# A31G12x_series register map
Vendor: ABOV Semiconductor Co., Ltd.; Series: A31G12x_series; File version: 1.0
CPU: CM0PLUS r0p1, little endian, no MPU, no FPU, VTOR, 2 interrupt priority bits
Registers are 32-bit, read-write, reset 0x0 unless marked. A register's access mark holds for its fields unless they carry their own. Offsets are from the block's base; [hi:lo] are bit positions; {n}, {i} and the like mark numbered series.

## xNVIC — NESTED VECTORED INTERRUPT CONTROLLER
Base 0xE000E100
0x00 ISER — Interrupt Set-enable Register
0x80 ICER — Interrupt Clear-enable Register
0x100 ISPR — Interrupt Set-pending Register
0x180 ICPR — Interrupt Clear-pending Register
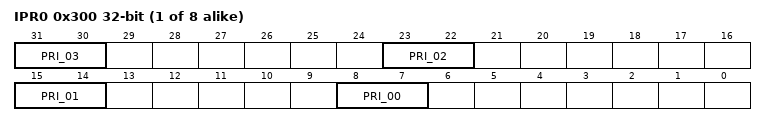
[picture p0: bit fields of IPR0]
{0x300+4i} IPR{i} (reset mask 0xC0C0C0C0) (i=0..7) — Interrupt Priority Register {i}
  [31:30] PRI_{4i+3:02} — IRQ {4i+3:02} Priority. The lower the value, the greater the priority of the corresponding interrupt.
  [23:22] PRI_{4i+2:02} — IRQ {4i+2:02} Priority. The lower the value, the greater the priority of the corresponding interrupt.
  [15:14] PRI_{4i+1:02} — IRQ {4i+1:02} Priority. The lower the value, the greater the priority of the corresponding interrupt.
  [8:7] PRI_{4i:02} — IRQ {4i:02} Priority. The lower the value, the greater the priority of the corresponding interrupt.

## xSCB — SYSTEM CONTROL BLOCK
Base 0xE000ED00
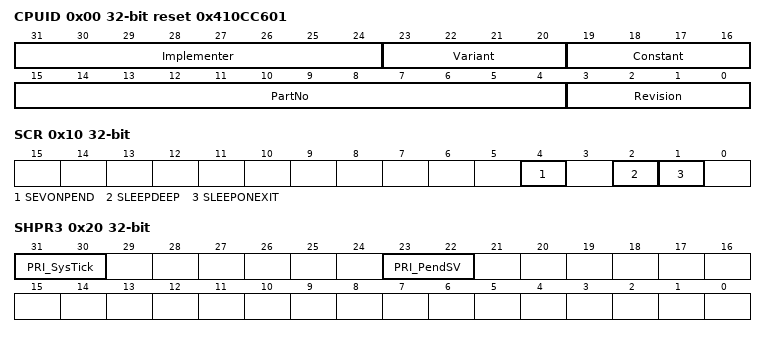
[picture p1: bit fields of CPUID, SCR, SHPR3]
0x00 CPUID ro reset 0x410CC601
  [31:24] Implementer — Implementer Code (0x41 corresponds to ARM)
  [23:20] Variant — Major revision number n in the rnpm revision status
  [19:16] Constant — Constant that defines the architecture of the processor (0xC corresponds to ARMv6-M architecture)
  [15:4] PartNo — Part number of the processor (0xC60 corresponds to Cortex-M0)
  [3:0] Revision — Minor revision number m in the rnpm revision status (0x1 corresponds to patch 1)
0x04 ICSR (reset mask 0x9E03F000) — Interrupt Control and State Register
0x08 VTOR (reset mask 0xFFFFFF80) — Vector Table Offset Register
0x0C AIRCR (reset mask 0xFFFF8006) — Application Interrupt and Reset Control Register
0x10 SCR — System Control Register
  [4] SEVONPEND — Send Event on Pending bit
  [2] SLEEPDEEP — Controls whether the processor uses sleep or deep sleep as its low power mode
  [1] SLEEPONEXIT — Indicates sleep-on-exit when returning from Handler mode to Thread mode
0x14 CCR ro (reset mask 0x208) — Configuration and Control Register
0x1C SHPR2 — System Handler Priority Register 2
  [31:30] PRI_SVCall — Priority of System Handler 11, SVCall. The lower the value, the greater the priority of the corresponding interrupt.
0x20 SHPR3 — System Handler Priority Register 3
  [31:30] PRI_SysTick — Priority of System Handler 15, SysTick. The lower the value, the greater the priority of the corresponding interrupt.
  [23:22] PRI_PendSV — Priority of System Handler 14, PendSV. The lower the value, the greater the priority of the corresponding interrupt.

## PA — General Port A
Base 0x30000000
Same registers: PB 0x30000100, PC 0x30000200, PD 0x30000300, PE 0x30000400, PF 0x30000500
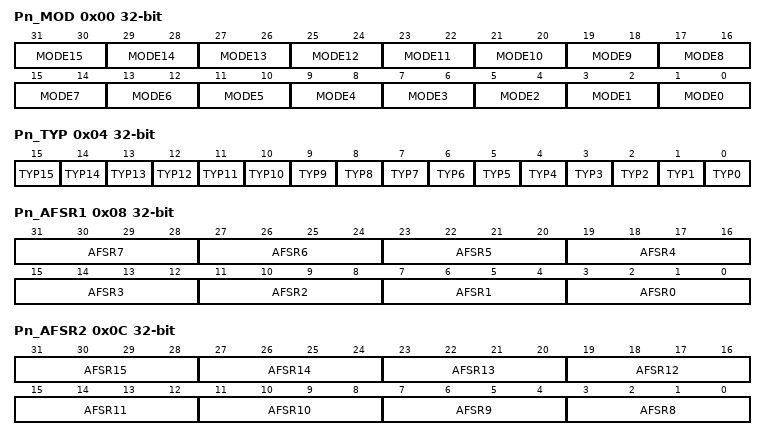
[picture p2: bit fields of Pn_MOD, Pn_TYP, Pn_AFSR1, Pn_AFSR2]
0x00 Pn_MOD — Port n Mode Register
  [2n+1:2n] MODE{n} (n=0..15) — Pin {n} Mode Selection bits
0x04 Pn_TYP — Port n Output Type Selection Register
  [n] TYP{n} (n=0..15) — Pin {n} Output Type Selection bit
0x08 Pn_AFSR1 — Port n Alternative Function Selection Register 1
  [4n+3:4n] AFSR{n} (n=0..7) — Pin {n} Alternative Function Selection bits
0x0C Pn_AFSR2 — Port n Alternative Function Selection Register 2
  [4n-29:4n-32] AFSR{n} (n=8..15) — Pin {n} Alternative Function Selection bits
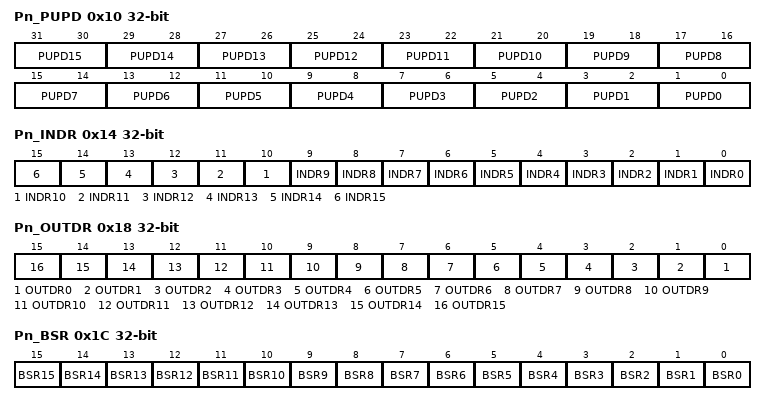
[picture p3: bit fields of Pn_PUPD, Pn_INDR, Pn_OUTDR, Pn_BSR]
0x10 Pn_PUPD — Port n Pull-up/down Resistor Selection Register
  [2n+1:2n] PUPD{n} (n=0..15) — Pin {n} Pull-up/down Resistor Selection bits
0x14 Pn_INDR ro — Port n Input Data Register
  [n] INDR{n} (n=0..15) — Pin {n} Input Data bit
0x18 Pn_OUTDR — Port n Output Data Register
  [n] OUTDR{n} (n=0..15) — Pin {n} Output Data bit
0x1C Pn_BSR wo — Port n Output Bit Set Register
  [n] BSR{n} (n=0..15) — Pin {n} Output Set bit. This bit is always read to 0
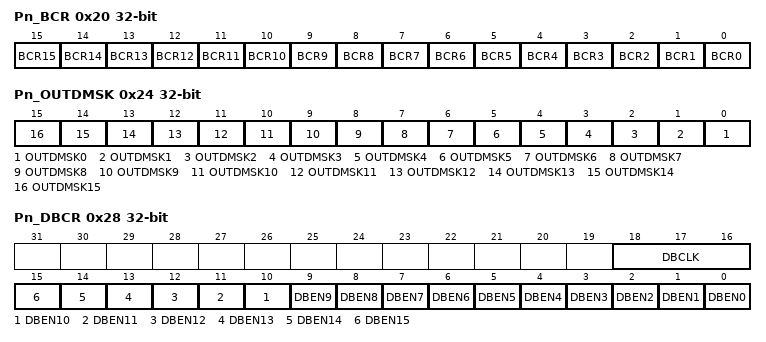
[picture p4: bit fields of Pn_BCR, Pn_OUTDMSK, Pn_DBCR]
0x20 Pn_BCR wo — Port n Output Bit Clear Register
  [n] BCR{n} (n=0..15) — Pin {n} Output Clear bit. This bit is always read to 0.
0x24 Pn_OUTDMSK — Port n Output Data Mask Register
  [n] OUTDMSK{n} (n=0..15) — Pin {n} Output Data Mask bit
0x28 Pn_DBCR — Port n Debounce Control Register
  [18:16] DBCLK — Port n Debounce Filter Sampling Clock Selection bits
  [n] DBEN{n} (n=0..15) — Pin {n} Debounce Enable bit
